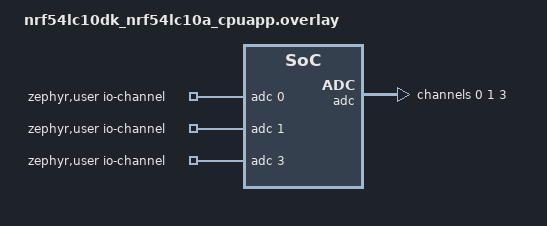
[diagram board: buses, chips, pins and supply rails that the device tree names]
/*
 * Copyright (c) 2026 Nordic Semiconductor ASA
 *
 * SPDX-License-Identifier: LicenseRef-Nordic-5-Clause
 */

/* Same channel wiring as nRF54LV10 DK (see nrf54lv10dk_nrf54lv10a_cpuapp.overlay). */

/ {
	zephyr,user {
		io-channels = <&adc 0>, <&adc 1>, <&adc 3>;
	};
};

&adc {
	#address-cells = <1>;
	#size-cells = <0>;
	status = "okay";

	channel@0 {
		reg = <0>;
		zephyr,gain = "ADC_GAIN_1";
		zephyr,reference = "ADC_REF_INTERNAL";
		zephyr,acquisition-time = <ADC_ACQ_TIME_DEFAULT>;
		zephyr,input-positive = <NRF_SAADC_AIN0>; /* P1.00 */
		zephyr,resolution = <10>;
	};

	channel@1 {
		reg = <1>;
		zephyr,gain = "ADC_GAIN_1";
		zephyr,reference = "ADC_REF_INTERNAL";
		zephyr,acquisition-time = <ADC_ACQ_TIME_DEFAULT>;
		zephyr,input-positive = <NRF_SAADC_AIN1>; /* P1.01 */
		zephyr,resolution = <12>;
		zephyr,oversampling = <8>;
	};

	channel@3 {
		reg = <3>;
		zephyr,gain = "ADC_GAIN_1";
		zephyr,reference = "ADC_REF_INTERNAL";
		zephyr,acquisition-time = <ADC_ACQ_TIME_DEFAULT>;
		zephyr,input-positive = <NRF_SAADC_AIN5>; /* P1.10 */
		zephyr,input-negative = <NRF_SAADC_AIN6>; /* P1.11 */
		zephyr,resolution = <12>;
	};
};
